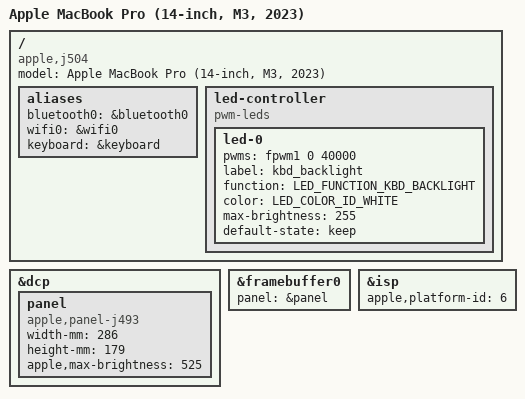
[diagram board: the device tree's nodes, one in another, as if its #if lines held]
// SPDX-License-Identifier: GPL-2.0+ OR MIT
/*
 * MacBook Pro (14-inch, 2023)
 *
 * This file contains the parts for t6030.
 *
 * target-type: J514s 
 *
 * Copyright The Asahi Linux Contributors
 */

/dts-v1/;

#include "t6030.dtsi"
#include "t6030-jxxx.dtsi"
#include <dt-bindings/leds/common.h>

/ {
	compatible = "apple,j504", "apple,t6030", "apple,arm-platform";
	model = "Apple MacBook Pro (14-inch, M3, 2023)";

	aliases {
#ifdef T6030_BRINGUP_UNKNOWN
		bluetooth0 = &bluetooth0;
		wifi0 = &wifi0;
		keyboard = &keyboard;
#endif // T6030_BRINGUP_UNKNOWN
	};

#ifdef T6030_BRINGUP_UNKNOWN
	led-controller {
		compatible = "pwm-leds";
		led-0 {
			pwms = <&fpwm1 0 40000>;
			label = "kbd_backlight";
			function = LED_FUNCTION_KBD_BACKLIGHT;
			color = <LED_COLOR_ID_WHITE>;
			max-brightness = <255>;
			default-state = "keep";
		};
	};
#endif // T6030_BRINGUP_UNKNOWN
};

#ifdef T6030_BRINGUP_UNKNOWN
&dcp {
	panel: panel {
		compatible = "apple,panel-j493", "apple,panel";
		width-mm = <286>;
		height-mm = <179>;
		apple,max-brightness = <525>;
	};
};

&framebuffer0 {
	panel = &panel;
};

/*
 * Force the bus number assignments so that we can declare some of the
 * on-board devices and properties that are populated by the bootloader
 * (such as MAC addresses).
 */
#if 0
&port00 {
	bus-range = <1 1>;
	pwren-gpios = <&smc_gpio 13 GPIO_ACTIVE_HIGH>;
	wifi0: wifi@0,0 {
		compatible = "pci14e4,4425";
		reg = <0x10000 0x0 0x0 0x0 0x0>;
		/* To be filled by the loader */
		local-mac-address = [00 00 00 00 00 00];
		apple,antenna-sku = "XX";
		brcm,board-type = "apple,kyushu";
	};

	bluetooth0: bluetooth@0,1 {
		compatible = "pci14e4,5f69";
		reg = <0x10100 0x0 0x0 0x0 0x0>;
		/* To be filled by the loader */
		local-bd-address = [00 00 00 00 00 00];
		brcm,board-type = "apple,kyushu";
	};
};
#endif

#if 0
/*
 * Provide labels for the USB type C ports.
 */
&typec0 {
	label = "USB-C Left-back";
};

&typec1 {
	label = "USB-C Left-front";
};

/* Virtual regulator representing the shared shutdown GPIO */
/ {
	speaker_sdz: fixed-regulator-sn012776-sdz {
		compatible = "regulator-fixed";
		regulator-name = "sn012776-sdz";
		startup-delay-us = <5000>;
		gpios = <&pinctrl_ap 88 GPIO_ACTIVE_HIGH>;
		enable-active-high;
	};
};

&i2c1 {
	speaker_left_rear: codec@38 {
		compatible = "ti,sn012776", "ti,tas2764";
		reg = <0x38>;
		SDZ-supply = <&speaker_sdz>;
		#sound-dai-cells = <0>;
		sound-name-prefix = "Left Rear";
		interrupts-extended = <&pinctrl_ap 11 IRQ_TYPE_LEVEL_LOW>;
		ti,imon-slot-no = <8>;
		ti,vmon-slot-no = <10>;
	};

	speaker_left_front: codec@39 {
		compatible = "ti,sn012776", "ti,tas2764";
		reg = <0x39>;
		SDZ-supply = <&speaker_sdz>;
		#sound-dai-cells = <0>;
		sound-name-prefix = "Left Front";
		interrupts-extended = <&pinctrl_ap 11 IRQ_TYPE_LEVEL_LOW>;
		ti,imon-slot-no = <0>;
		ti,vmon-slot-no = <2>;
		ti,sdout-force-zero-mask = <0xf0f0>;
	};
};

&i2c3 {
	speaker_right_rear: codec@3b {
		compatible = "ti,sn012776", "ti,tas2764";
		reg = <0x3b>;
		SDZ-supply = <&speaker_sdz>;
		#sound-dai-cells = <0>;
		sound-name-prefix = "Right Rear";
		interrupts-extended = <&pinctrl_ap 11 IRQ_TYPE_LEVEL_LOW>;
		ti,imon-slot-no = <12>;
		ti,vmon-slot-no = <14>;
	};

	speaker_right_front: codec@3c {
		compatible = "ti,sn012776", "ti,tas2764";
		reg = <0x3c>;
		SDZ-supply = <&speaker_sdz>;
		#sound-dai-cells = <0>;
		sound-name-prefix = "Right Front";
		interrupts-extended = <&pinctrl_ap 11 IRQ_TYPE_LEVEL_LOW>;
		ti,imon-slot-no = <4>;
		ti,vmon-slot-no = <6>;
		ti,sdout-force-zero-mask = <0x0f0f>;
	};

	jack_codec: codec@4b {
		compatible = "cirrus,cs42l84";
		reg = <0x4b>;
		reset-gpios = <&pinctrl_nub 12 GPIO_ACTIVE_HIGH>;
		#sound-dai-cells = <0>;
		interrupts-extended = <&pinctrl_ap 149 IRQ_TYPE_LEVEL_LOW>;
		sound-name-prefix = "Jack";
	};
};

&i2c4 {
	status = "okay";
};

&fpwm1 {
	status = "okay";
};

/ {
	sound {
		compatible = "apple,j504-macaudio", "apple,macaudio";
		model = "MacBook Pro J504";

		dai-link@0 {
			link-name = "Speakers";

			cpu {
				sound-dai = <&mca 0>, <&mca 1>;
			};
			codec {
				sound-dai = <&speaker_left_front>, <&speaker_left_rear>,
					    <&speaker_right_front>, <&speaker_right_rear>;
			};
		};

		dai-link@1 {
			link-name = "Headphone Jack";

			cpu {
				sound-dai = <&mca 2>;
			};
			codec {
				sound-dai = <&jack_codec>;
			};
		};
	};
};
#endif

#if 0
&mtp {
	status = "okay";
};
&mtp_mbox {
	status = "okay";
};
&mtp_dart {
	status = "okay";
};
&mtp_dockchannel {
	status = "okay";
};
&mtp_hid {
	apple,afe-reset-gpios = <&smc_gpio 8 GPIO_ACTIVE_LOW>;
	apple,stm-reset-gpios = <&smc_gpio 24 GPIO_ACTIVE_LOW>;

	multi-touch {
		firmware-name = "apple/tpmtfw-j504.bin";
	};

	keyboard: keyboard {
		hid-country-code = <0>;
		apple,keyboard-layout-id = <0>;
	};

	stm {
	};

	actuator {
	};

	tp_accel {
	};
};
#endif

#include "isp-imx248.dtsi"

&isp {
	apple,platform-id = <6>;
};
#endif // T6030_BRINGUP_UNKNOWN
